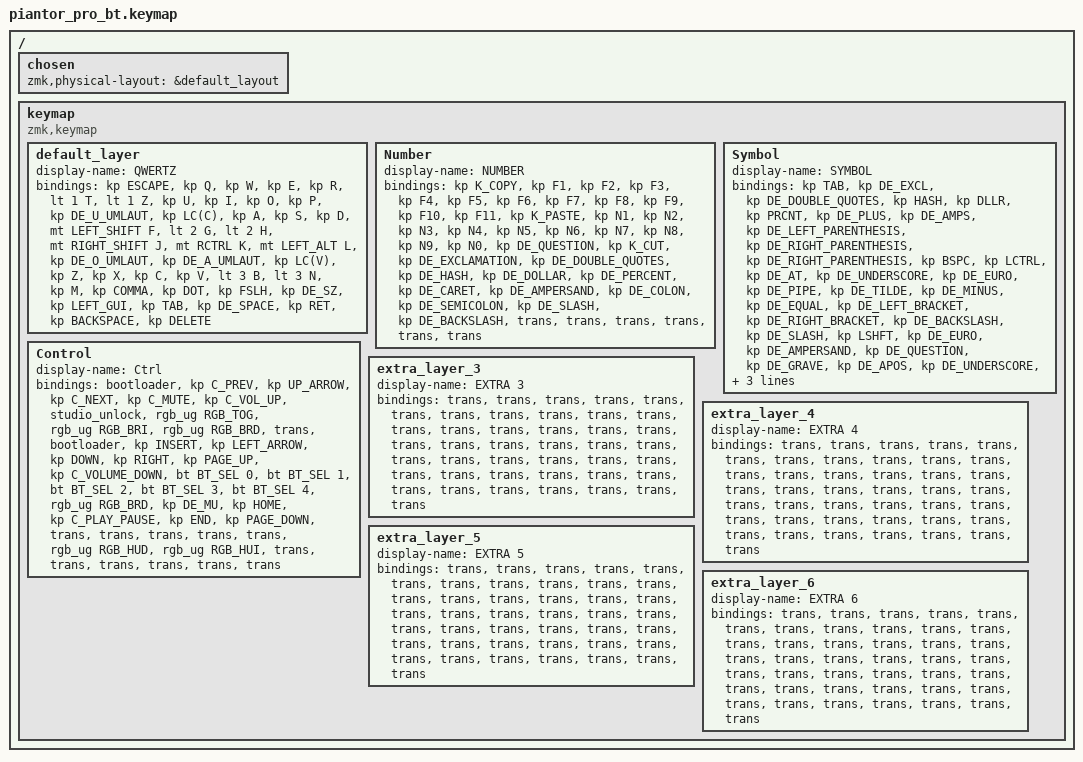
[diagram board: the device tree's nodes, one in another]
/*
 * Copyright (c) 2020 The ZMK Contributors
 *
 * SPDX-License-Identifier: MIT
 */

#include <behaviors.dtsi>
#include <dt-bindings/zmk/bt.h>
#include <dt-bindings/zmk/keys.h>
#include <dt-bindings/zmk/rgb.h>
#include "keys_de.h"

/ {
    chosen { zmk,physical-layout = &default_layout; };
};

/ {
    keymap {
        compatible = "zmk,keymap";

        default_layer {
            display-name = "QWERTZ";

            // --------------------------------------------------------------------------------
            // |  TAB |  Q  |  W  |  E  |  R  |  T  |  Y  |  U   |  I  |  O  |  P  | BSPC |
            // | CTRL |  A  |  S  |  D  |  F  |  G  |  H  |  J   |  K  |  L  |  ;  |  '   |
            // | SHFT |  Z  |  X  |  C  |  V  |  B  |  N  |  M   |  ,  |  .  |  /  | ESC  |
            //                    | GUI | LWR | SPC | ENT | RSE  | ALT |

            bindings = <
&kp ESCAPE  &kp Q  &kp W  &kp E  &kp R  &lt 1 T  &lt 1 Z  &kp U  &kp I  &kp O  &kp P  &kp DE_U_UMLAUT  &kp LC(C)  &kp A  &kp S  &kp D  &mt LEFT_SHIFT F  &lt 2 G  &lt 2 H  &mt RIGHT_SHIFT J  &mt RCTRL K  &mt LEFT_ALT L  &kp DE_O_UMLAUT  &kp DE_A_UMLAUT  &kp LC(V)  &kp Z  &kp X  &kp C  &kp V  &lt 3 B  &lt 3 N  &kp M  &kp COMMA  &kp DOT  &kp FSLH  &kp DE_SZ  &kp LEFT_GUI  &kp TAB  &kp DE_SPACE  &kp RET  &kp BACKSPACE  &kp DELETE
            >;
        };

        Number {
            display-name = "NUMBER";

            // -----------------------------------------------------------------------------------------
            // |  TAB |  1  |  2  |  3  |  4  |  5    |  6  |  7  |  8  |  9  |  0  | BSPC |
            // | CTRL | BT1 | BT2 | BT3 | BT4 | BT5   | LFT | DWN |  UP | RGT |     |      |
            // | SHFT | BTCR| RGB | RST | BOOT| Unlock|     |     |     |     |     |      |
            //                    | GUI |     | SPC   | ENT |     | ALT |

            bindings = <
&kp K_COPY  &kp F1  &kp F2  &kp F3  &kp F4  &kp F5  &kp F6  &kp F7  &kp F8  &kp F9  &kp F10  &kp F11  &kp K_PASTE  &kp N1  &kp N2  &kp N3  &kp N4  &kp N5  &kp N6  &kp N7  &kp N8  &kp N9  &kp N0  &kp DE_QUESTION  &kp K_CUT  &kp DE_EXCLAMATION  &kp DE_DOUBLE_QUOTES  &kp DE_HASH  &kp DE_DOLLAR  &kp DE_PERCENT  &kp DE_CARET  &kp DE_AMPERSAND  &kp DE_COLON  &kp DE_SEMICOLON  &kp DE_SLASH  &kp DE_BACKSLASH  &trans  &trans  &trans  &trans  &trans  &trans
            >;
        };

        Symbol {
            display-name = "SYMBOL";

            // -----------------------------------------------------------------------------------------
            // |  TAB |  !  |  @  |  #  |  $  |  %  |  ^  |  &  |  *  |  (  |  )  | BSPC |
            // | CTRL | HUD | HUI |     |     |     |  -  |  =  |  [  |  ]  |  \  |  `   |
            // | SHFT |     |     |     |     |     |  _  |  +  |  {  |  }  | "|" |  ~   |
            //                    | GUI |     | SPC | ENT |     | ALT |

            bindings = <
&kp TAB  &kp DE_EXCL  &kp DE_DOUBLE_QUOTES  &kp HASH  &kp DLLR  &kp PRCNT  &kp DE_PLUS  &kp DE_AMPS  &kp DE_LEFT_PARENTHESIS  &kp DE_RIGHT_PARENTHESIS  &kp DE_RIGHT_PARENTHESIS  &kp BSPC  &kp LCTRL  &kp DE_AT  &kp DE_UNDERSCORE  &kp DE_EURO  &kp DE_PIPE  &kp DE_TILDE  &kp DE_MINUS  &kp DE_EQUAL  &kp DE_LEFT_BRACKET  &kp DE_RIGHT_BRACKET  &kp DE_BACKSLASH  &kp DE_SLASH  &kp LSHFT  &kp DE_EURO  &kp DE_AMPERSAND  &kp DE_QUESTION  &kp DE_GRAVE  &kp DE_APOS  &kp DE_UNDERSCORE  &kp DE_PLUS  &kp DE_LT  &kp DE_GT  &kp DE_LEFT_BRACE  &kp DE_RIGHT_BRACE  &trans  &trans  &trans  &trans  &trans  &trans
            >;
        };

        Control {
            display-name = "Ctrl";
            bindings = <
&bootloader  &kp C_PREV  &kp UP_ARROW  &kp C_NEXT  &kp C_MUTE  &kp C_VOL_UP  &studio_unlock  &rgb_ug RGB_TOG  &rgb_ug RGB_BRI  &rgb_ug RGB_BRD  &trans  &bootloader  &kp INSERT  &kp LEFT_ARROW  &kp DOWN  &kp RIGHT  &kp PAGE_UP  &kp C_VOLUME_DOWN  &bt BT_SEL 0  &bt BT_SEL 1  &bt BT_SEL 2  &bt BT_SEL 3  &bt BT_SEL 4  &rgb_ug RGB_BRD  &kp DE_MU  &kp HOME  &kp C_PLAY_PAUSE  &kp END  &kp PAGE_DOWN  &trans  &trans  &trans  &trans  &trans  &rgb_ug RGB_HUD  &rgb_ug RGB_HUI  &trans  &trans  &trans  &trans  &trans  &trans
            >;
        };

        extra_layer_3 {
            display-name = "EXTRA 3";
            bindings = <
&trans  &trans  &trans  &trans  &trans  &trans  &trans  &trans  &trans  &trans  &trans  &trans  &trans  &trans  &trans  &trans  &trans  &trans  &trans  &trans  &trans  &trans  &trans  &trans  &trans  &trans  &trans  &trans  &trans  &trans  &trans  &trans  &trans  &trans  &trans  &trans  &trans  &trans  &trans  &trans  &trans  &trans
            >;
        };

        extra_layer_4 {
            display-name = "EXTRA 4";
            bindings = <
&trans  &trans  &trans  &trans  &trans  &trans  &trans  &trans  &trans  &trans  &trans  &trans  &trans  &trans  &trans  &trans  &trans  &trans  &trans  &trans  &trans  &trans  &trans  &trans  &trans  &trans  &trans  &trans  &trans  &trans  &trans  &trans  &trans  &trans  &trans  &trans  &trans  &trans  &trans  &trans  &trans  &trans
            >;
        };

        extra_layer_5 {
            display-name = "EXTRA 5";
            bindings = <
&trans  &trans  &trans  &trans  &trans  &trans  &trans  &trans  &trans  &trans  &trans  &trans  &trans  &trans  &trans  &trans  &trans  &trans  &trans  &trans  &trans  &trans  &trans  &trans  &trans  &trans  &trans  &trans  &trans  &trans  &trans  &trans  &trans  &trans  &trans  &trans  &trans  &trans  &trans  &trans  &trans  &trans
            >;
        };

        extra_layer_6 {
            display-name = "EXTRA 6";
            bindings = <
&trans  &trans  &trans  &trans  &trans  &trans  &trans  &trans  &trans  &trans  &trans  &trans  &trans  &trans  &trans  &trans  &trans  &trans  &trans  &trans  &trans  &trans  &trans  &trans  &trans  &trans  &trans  &trans  &trans  &trans  &trans  &trans  &trans  &trans  &trans  &trans  &trans  &trans  &trans  &trans  &trans  &trans
            >;
        };
    };
};
